# N32G032 register map
Vendor: Nationstech Ltd.; File version: 1.0
Registers are 32-bit, read-write, reset 0x0 unless marked. A register's access mark holds for its fields unless they carry their own. Offsets are from the block's base; lines under a group give offsets from that group; [hi:lo] are bit positions; {n}, {i} and the like mark numbered series; 'fields as' and 'values as' point back to an identical list; <NAME> marks a mode.

## Memory map
0x40000000 BEEPER1 size 0x400 — Beeper unit
0x40000400 TIM3 size 0x400 — General purpose timer
0x40000800 TIM4 size 0x400
0x40000C00 LPTIM size 0x400 — Low power timer control
0x40001000 TIM6 size 0x400 — Basic timer
0x40001400 BEEPER2 size 0x400
0x40002000 OPAMP size 0x400 — operational amplifier
0x40002400 COMP size 0x400 — comparator
0x40002800 RTC size 0x400 — Real time clock
0x40002C00 WWDG size 0x400 — window watchdog
0x40003000 IWDG size 0x400 — Independent watchdog
0x40003400 TSC size 0x400 — touch screen control
0x40004400 USART2 size 0x400
0x40004800 LPUART1 size 0x400 — Low-power universal asynchronous receiver transmitter
0x40004C00 LPUART2 size 0x400
0x40005000 UART5 size 0x400 — Universal asynchronous receiver transmitter
0x40005400 I2C1 size 0x400 — Inter integrated circuit
0x40005800 I2C2 size 0x400
0x40006400 CAN size 0x400 — Controller area network
0x40007000 PWR size 0x400 — Power control
0x40010000 AFIO size 0x400 — Alternate function I/O
0x40010400 EXTI size 0x400 — external interrupt/event controller
0x40010800 GPIOA size 0x400 — General purpose I/O
0x40010C00 GPIOB size 0x400
0x40011000 GPIOC size 0x400
0x40011400 GPIOD size 0x400
0x40011C00 GPIOF size 0x400
0x40012000 SPI1 size 0x400 — Serial peripheral interface
0x40012C00 TIM1 size 0x400 — Advanced timer
0x40013000 SPI3 size 0x400 — Serial peripheral interface
0x40013400 TIM8 size 0x400 — Advanced timer
0x40013800 USART1 size 0x400 — Universal synchronous asynchronous receiver transmitter
0x40014400 SPI2 size 0x400 — Serial peripheral interface
0x40015000 UART6 size 0x400
0x40020000 DMA size 0x400 — Direct memory access controller
0x40020400 SQRT size 0x400 — Square Root Calculations
0x40020800 ADC size 0x400 — analog to digital converter
0x40021000 RCC size 0x400 — Reset and clock control
0x40022000 FLASH size 0x400 — interal FLASH controller
0x40023000 CRC size 0x400 — cyclic redundancy check
0x40028000 HDIV size 0x400 — High-speed divider

## Interrupts
0 WWDG — WWDG interrupt
1 PVD (PWR) — PVD through EXTI line detection interrupt
2 RTC — RTC global interrupt
4 FLASH — FLASH interrupt
5 RCC — RCC interrupt
6 EXTI0_1 (EXTI) — EXTI0/1 interrupt
7 EXTI2_3 (EXTI) — EXTI2/3 interrupt
8 EXTI4_15 (EXTI) — EXTI4/5/6/7/8/9/10/11/12/13/14/15 interrupt
9 TSC — TSC global interrupt
11 DMA_Channel1_2_3_4 (DMA) — DMA channel1 channel2 channel3 channel4 interrupt
12 DMA_Channel5_6_7_8 (DMA) — DMA channel5 channel6 channel7 channel8 interrupt
13 TIM1_BRK (TIM1) — TIM1 Break/Update/Trigger/Commutation interrupt
14 TIM1_CC (TIM1) — TIM1 Capture Compare interrupt
15 CAN — CAN TX/RX0/RX1/SCE interrupts
16 TIM3 — TIM3 global interrupt
17 TIM4 — TIM4 global interrupt
18 TIM8_BRK (TIM8) — TIM8 Break/Update/Trigger/Commutation interrupt
19 TIM8_CC (TIM8) — TIM8 Capture Compare interrupt
20 LPTIM_TIM6 (LPTIM) — LPTIM / TIM6 global Interrupts
21 ADC — ADC global interrupt
22 SPI2_3 (SPI2, SPI3) — SPI2/3 global interrupt
23 I2C1 — I2C1 global interrupt
24 I2C2 — I2C2 Global interrupt
25 SPI1 — SPI1 global interrupt
26 HDIV_SQRT (HDIV, SQRT) — HDIV/SQRT interrupt
28 USART1_2 (USART1) — USART1/2 global interrupt
29 LPUART1_2 (LPUART1, LPUART2) — LPUART1/2 global interrupt
30 UART5_6 (UART5) — UART5/6 global interrupt
31 COMP_1_2_3 (COMP) — COMP1/2/3 interrupt

## ADC — analog to digital converter
Base 0x40020800
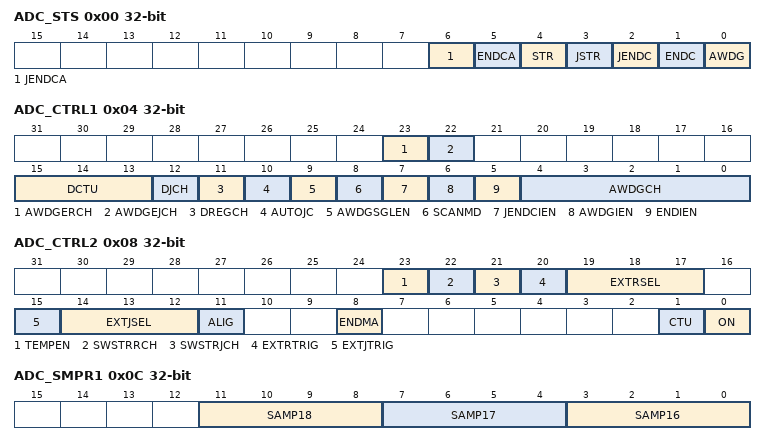
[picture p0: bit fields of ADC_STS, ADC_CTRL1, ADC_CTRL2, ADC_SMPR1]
0x00 ADC_STS
  [6] JENDCA, [5] ENDCA, [4] STR, [3] JSTR, [2] JENDC, [1] ENDC, [0] AWDG
0x04 ADC_CTRL1 (reset mask 0xB0FFFF)
  [23] AWDGERCH, [22] AWDGEJCH, [15:13] DCTU, [12] DJCH, [11] DREGCH, [10] AUTOJC, [9] AWDGSGLEN, [8] SCANMD, [7] JENDCIEN, [6] AWDGIEN, [5] ENDIEN, [4:0] AWDGCH
0x08 ADC_CTRL2
  [23] TEMPEN, [22] SWSTRRCH, [21] SWSTRJCH, [20] EXTRTRIG, [19:17] EXTRSEL, [15] EXTJTRIG, [14:12] EXTJSEL, [11] ALIG, [8] ENDMA, [1] CTU, [0] ON
0x0C ADC_SMPR1
  [11:8] SAMP18, [7:4] SAMP17, [3:0] SAMP16
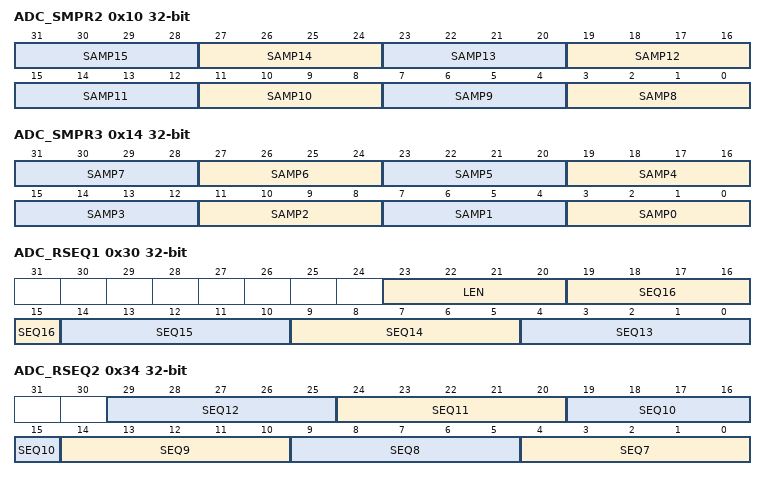
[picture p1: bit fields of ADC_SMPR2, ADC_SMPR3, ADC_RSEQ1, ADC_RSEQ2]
0x10 ADC_SMPR2
  [4n-29:4n-32] SAMP{n} (n=8..15)
0x14 ADC_SMPR3
  [4n+3:4n] SAMP{n} (n=0..7)
{0x14+4i} ADC_JOFFSET{i} (i=1..4)
  [11:0] OFFSETJCH{i}
0x28 ADC_WDGHIGH
  [11:0] HTH
0x2C ADC_WDGLOW
  [11:0] LTH
0x30 ADC_RSEQ1
  [23:20] LEN, [5n-61:5n-65] SEQ{n} (n=13..16)
0x34 ADC_RSEQ2
  [5n-31:5n-35] SEQ{n} (n=7..12)
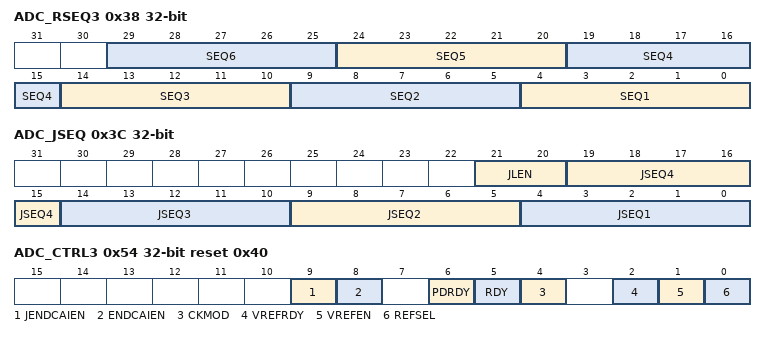
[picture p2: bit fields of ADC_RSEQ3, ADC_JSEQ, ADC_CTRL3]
0x38 ADC_RSEQ3
  [5n-1:5n-5] SEQ{n} (n=1..6)
0x3C ADC_JSEQ
  [21:20] JLEN, [5n-1:5n-5] JSEQ{n} (n=1..4)
{0x3C+4i} ADC_JDAT{i} (i=1..4)
  [15:0] JDAT{i}
0x50 ADC_DAT
  [15:0] DAT
0x54 ADC_CTRL3 reset 0x40
  [9] JENDCAIEN, [8] ENDCAIEN, [6] PDRDY, [5] RDY, [4] CKMOD, [2] VREFRDY, [1] VREFEN, [0] REFSEL
